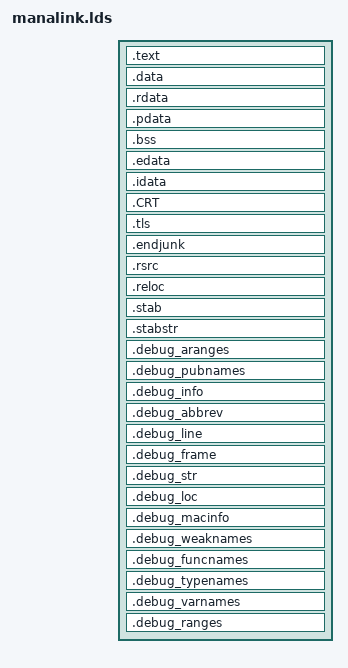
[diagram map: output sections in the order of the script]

/* Global variables */
/*old _cards_ptr = 0x55d0e0;*/
_ability_tooltip_names_exe = 0x738260;
_active_cards_count = 0x4EF520;
_affected_card = 0x7A398C;
_affected_card_controller = 0x738C84;
_ai_defensive_modifier = 0x78fba4;
_ai_modifier = 0x7A31A8;
_ante = 0x738C88;
_ante_cards = 0x505728;
_artifact_count = 0x4ef1d4;
_attacking_card = 0x739198;
_attacking_card_controller = 0x7a3498;
_basiclandtypes_controlled = 0x4ef460;
_cancel = 0x4EF194;	/* == _spell_fizzled */
_cant_be_responded_to = 0x628b34;
_cards_data = 0x7E7010;
_card_on_stack = 0x739190;
_card_on_stack_controller = 0x739194;
_cards_drawn_this_turn = 0x4ef1f4;
_cards_ptr = 0x73bb00;
_cards_txt = 0x73bae4;
_charge_mana_addr_of_pre_mana_pool = 0x4d9434;
_charge_mana_addr_of_x_value = 0x4d9438;
_charge_mana_addr_of_pay_mana_xbugrw = 0x4d943c;
_charge_mana_addr_of_max_x_value = 0x4d9440;
_coin_flip = 0x470690;
_colors_of_lands_in_play = 0x60a568;
_creature_count = 0x4ef1cc;
_current_phase = 0x4EF184;
_current_turn = 0x628670;
_damage_card = 0x7904f8;
_debug_mode = 0x628530;
_Deck = 0x7a588c;
_deck_ptr = 0x4d7030;
_displayed_x_value = 0x60A438;
_enchantment_count = 0x4ef1dc;
_event_flags = 0x4ef188;
_event_result = 0x6205B4;
_forbid_attack = 0x6205b0;
_game_number = 0x739A18;
_game_type = 0x73bad4;
_gauntlet_round = 0x78FA6C;
_graveyard_ptr_mutable = 0x4D7018;
_hand_count = 0x4EF1C4;
_hunting_subtypes = 0x7906B7;
_initial_library = 0x56595c;
_land_can_be_played = 0x4ef190;
_lands_played = 0x4EF1FC;
_ldoubleclicked = 0x60a440;
_life = 0x4EF528;
_life_gained = 0x73b6ac;
_landsofcolor_controlled = 0x4ef4a0;
_mana_doesnt_drain_from_pool = 0x4ef200;
_max_x_value = 0x4ef198;
_must_attack = 0x4EF170;
_needed_mana_colors = 0x7a2b68;
_number_of_attackers_declared = 0x4ef20e;
_opponent_name = 0x628b70;
_opponent_skill = 0x60A430;
_option_PhaseStoppers = 0x62c374;
_player_bits = 0x4ef1a4;
_pumpable_power = 0x628C80;
_pumpable_toughness = 0x628C88;
_player_counters = 0x4EF530;
_raw_card_instances = 0x4ef540;
_raw_displayed_card_instances = 0x543c10;
_raw_mana_available = 0x4ef3c0;
_raw_mana_available_hex = 0x4EF21C;
_reason_for_trigger_controller = 0x737E1C;
_rfg_ptr = 0x4d7024;
_spell_fizzled = 0x4EF194;	/* == _cancel */
_start_usertime_of_current_thread_in_ms = 0x56bf64;
_suppress_draw = 0x786DC8;
_tapped_for_mana_color = 0x7904bc;
_text_lines = 0x715CAC;
_timestamp_card = 0x5076f0;
_timestamp_player = 0x507ec0;
_total_power_of_creatures_by_color = 0x739d60;
_total_toughness_of_creatures_by_color = 0x73a230;
_trigger_cause = 0x739A20;
_trigger_cause_controller = 0x62C17C;
_trigger_condition = 0x7A2D78;
_turn_count = 0x78F260;
_types_of_cards_in_graveyard = 0x4ef174;
_types_of_cards_on_bf = 0x4ef17c;
_x_value = 0x4EF1A0;
/*_u55F028 = 0x55F028;*/	/* now at 7c7000 */
_time_walk_flag = 0x4EF18C;
_types_that_dont_untap = 0x78FBA0;
_mana_paid = 0x55CED0;
_mana_pool = 0x4EF4E0;
_available_slots = 0x7375ac;
/*For older versions _card_coded = 0x4EB7F8*/
_card_coded = 0x75C000;
_creatures_dead_this_turn = 0x4EF1F8;
_activation_card = 0x785F90;
_ai_is_speculating = 0x728574;
_stack_cards = 0x5096B0;
_stack_damage_targets = 0x5097b0;
_stack_data = 0x509630;
_stack_phase = 0x715700;
_stack_size = 0x5057A8;
_dword_4EF1B8 = 0x4EF1B8;
_strs_words_to_hack = 0x620d9c;
_strs_words_hacked = 0x787b08;
_num_words_to_hack = 0x738c80;
_strs_words_to_sleight = 0x618d4c;
_strs_words_sleighted = 0x72917c;
_num_words_to_sleight = 0x620d58;

_iid_draw_a_card = 0x735ed4;

_LEGACY_EFFECT_ALADDIN = 0x73bad8;
_LEGACY_EFFECT_ASTERISK = 0x7a3728;
_LEGACY_EFFECT_CHANNEL = 0x7281b8;
_LEGACY_EFFECT_PUMP = 0x790584;
_LEGACY_EFFECT_GENERIC = 0x737e58;
_LEGACY_EFFECT_ITH = 0x62c18c;
_LEGACY_EFFECT_ASWAN = 0x78FA68;
_LEGACY_EFFECT_DISINTEGRATE = 0x7371F8;
_LEGACY_EFFECT_SORCERESS_QUEEN = 0x73b578;
_LEGACY_EFFECT_STONING = 0x7366d4;
_LEGACY_EFFECT_TIME_WALK = 0x737E58;
/*_LEGACY_EFFECT_SIRENS_CALL = 0x620480;*/

/* this is the constant for the rukh egg legacy, that we have changed the code for. */
_LEGACY_EFFECT_CUSTOM = 0x735ed0;
/* And this was Nafs Asp's. */
_LEGACY_EFFECT_ACTIVATED = 0x7286F4;

_pay_mana_xbugrwaU =	0x4EF400;
_PAY_MANA_COLORLESS =	0x4EF400;
_PAY_MANA_BLACK =	0x4EF404;
_PAY_MANA_BLUE =	0x4EF408;
_PAY_MANA_GREEN =	0x4EF40C;
_PAY_MANA_RED =		0x4EF410;
_PAY_MANA_WHITE =	0x4EF414;
_PAY_MANA_ARTIFACT =	0x4EF418;

_MANA_COLORLESS =	0x55CF10;
_MANA_BLACK =		0x55CF11;
_MANA_BLUE =		0x55CF12;
_MANA_GREEN =		0x55CF13;
_MANA_RED =		0x55CF14;
_MANA_WHITE =		0x55CF15;
_MANA_ARTIFACT =	0x55CF16;
_MANA_UNKNOWN =		0x55CF17;

_COST_COLORLESS =	0x55CF18;
_COST_BLACK =		0x55CF19;
_COST_BLUE =		0x55CF1A;
_COST_GREEN =		0x55CF1B;
_COST_RED =		0x55CF1C;
_COST_WHITE =		0x55CF1D;


/* Functions in the exe */
_add_card_to_hand_exe = 0x479620;
_add_one_mana_any_color = 0x4E8224;
_another_copy_attached = 0x4baeb0;
_aura_ability = 0x4bbf30;
_aura_pump = 0x4bc1e0;
_real_bounce_permanent = 0x4A65F0;
_cannot_block_exe = 0x0040B5E0;
_check_hand_for_type = 0x4E77DD;
_check_mana_multi = 0x402BE0;
_choose_a_card = 0x4a9750;
_choose_a_color_exe = 0x4721c0;
_choose_a_number = 0x472120;
_cop2 = 0x4bdc80;
_count_mana = 0x472400;
_damage_creature_or_player = 0x4C8B90;
_damage_player = 0x4A68A0;
/*_deathtouch = 0x4CA9E0;*/
_declare_mana_available = 0x49d430;
_declare_mana_available_hex = 0x49D240;
_discard_exe = 0x433540;
_discard_card_exe = 0x4337a0;
_dispatch_event = 0x4359b0;
_do_action_with_type_in_hand = 0x4E78CA;
_do_dialog = 0x471EB0;
_draw_cards_exe = 0x41C190;
_end_the_game = 0x46A220;
_fear_exe = 0x40B540;
_real_gain_life = 0x4596B0;
_get_random_creature_type = 0x401ca0;
_get_usertime_of_current_thread_in_ms = 0x472c90;
_has_mana = 0x49D510;
_is_tapped = 0x4E81FE;
_islandhome = 0x4C8D30;
_load_text = 0x401F2C;
_obliterate_top_card_of_stack = 0x436930;
_mana_producer_fixed = 0x47B6C0;
_not_dying = 0x471d30;
_pay_mana_maximally_satisfied = 0x42f130;
_produce_mana = 0x49D490;
_pro_black = 0x4CA440;
_real_lose_the_game = 0x4791F0;
_real_put_on_top_of_deck = 0x410FB0;
_raw_put_iid_on_top_of_deck = 0x479d80;
_rearrange_top_3 = 0x4E7483;
_redraw_libraries = 0x468750;
_regenerate = 0x4C5890;
_regenerate_green = 0x4C5AC0;
_regenerate_target_exe = 0x4c59c0;
_remove_card_from_deck = 0x479d10;
_should_ai_play = 0x4377b0;
_show_deck_exe = 0x479360;
_singleplayer_mode = 0x4e95a8;
_strs_hunting_subtypenames = 0x79066c;
_target_player = 0x4E7E26;
_try_to_pay_for_mana_by_autotapping = 0x42f4a0;
_type_tutor =0x4E585D;
_urzatron_parts = 0x459630;
_asp = 0x4c4520;
_trace_mode = 0x790640;
_unknown62BCEC = 0x62BCEC;
_zombie_regen = 0x4C7E30;
_put_card_on_stack = 0x4338F0;
_put_card_on_stack2 = 0x433850;
_internal_rand = 0x44E050;
_oubliette_effect = 0x4597F0;
_create_a_card_type = 0x4A6500;
_save_or_load_data = 0x49f500;
_dword_60A4B0 = 0x60A4B0;
_TENTATIVE_wait_for_network_result = 0x4A70C0;
_TENTATIVE_send_network_result = 0x4A6BC0;
_dblword_628C10 = 0x628C10;
_byte_628C0C = 0x628C0C;

/*_fopen = 0x4D5EE2;*/
/*_fprintf = 0x4D5F72;*/
/*_fclose = 0x4D5F5A;*/
/*_fwrite = 0x4D5EB8;*/
/*_fscanf = 0x4D5ECA;*/
/*_atoi = 0x4D5F42;*/
/*_strcmp = 0x4D5E88;*/
/*_memcmp = 0x4D5EAC;*/
/*_memcpy = 0x4D5280;*/
/*_memset = 0x4D5FBA;*/
/*_sprintf = 0x4D5E94;*/

_u4585f0 = 0x4585f0;
_u4b6860 = 0x4b6860;
_byte_786DD4 = 0x786DD4;
_dispatch_trigger_twice_once_with_each_player_as_reason = 0x4371A0;
_str_Draw_a_card = 0x7377dc;
_put_card_in_graveyard = 0x477EC0;
_call_sub_437E20_unless_ai_is_speculating = 0x471D60;

/* Cards in the exe */
_card_braingeyser_exe = 0x0041BB00;
_card_glorious_anthem = 0x403CD0;
_card_lich_exe = 0x00432300;
_card_magical_hack_exe = 0x4A45B0;
_card_manta_riders = 0x4D9790;
_card_master_decoy = 0x40E510;
_card_shock = 0x4134B0;
_card_sleight_of_mind_exe = 0x4A49F0;
_card_volcanic_hammer = 0x4A3F20;
_card_zombie_master_exe = 0x004E203F;
_card_fireball_exe = 0x40A980;
_card_disintegrate_exe = 0x41E850;
_card_spell_blast_exe = 0x40A740;
_card_power_sink_exe = 0x4A5150;
_card_detonate_exe = 0x41CEC0;
_card_whimsy_exe = 0x473F50;
_card_word_of_binding_exe = 0x41D150;
_card_winter_blast_exe = 0x4117C0;
_card_alabaster_potion_exe = 0x4A5730;
_card_farmstead_exe = 0x4314A0;
_card_ancestral_recall_exe = 0x4A2C50;
_card_swords_to_plowshares_exe =0x4A3750;
_card_guardian_angel_exe = 0x00474D90;
_card_river_boa = 0x0040D650;
_card_ghazban_ogre = 0x00452D40;
_card_relic_bind = 0x004B7310;
_card_assembly_worker_exe = 0x47AE00;

/*
_card_aladdin_exe = 0x450F90;
_card_animate_artifact_exe = 0x4B5ED0;
_card_aven_fisher_exe = 0x404BE0;
_card_aven_flock_exe = 0x4032F0;
_card_ball_lightning_exe = 0x4CA0F0;
_card_boomerang_exe = 0x42C6D0;
_card_coercion_exe = 0x405980;
_card_consecrate_land_exe = 0x4305E0;
_card_control_magic_exe = 0x4B64C0;
_card_counterspell_exe = 0x4A4FE0;
_card_crusade_exe = 0x4B8E60;
_card_drudge_skeletons_exe = 0x0042B170;
_card_evil_presence_exe = 0x4B8110;
_card_firebreathing_exe = 0x4BA0F0;
_card_hurr_jackal_exe = 0x4CB0F0;
_card_last_gasp_exe = 0x4DEB8F;
_card_lightning_blast_exe = 0x0040DFF0;
_card_lightning_bolt_exe = 0x4A3F20;
_card_lim_duls_high_guard_exe = 0x00405100;
_card_living_lands_exe = 0x4B4A80;
_card_memory_lapse_exe = 0x4DEF65;
_card_orcish_oriflamme_exe = 0x004B8DD0;
_card_pit_scorpion_exe = 0x4C4390;
_card_prodigal_sorcerer_exe = 0x004C8800;
_card_pyroclasm_exe = 0x411280;
_card_remove_soul_exe = 0x0042CEF0;
_card_ring_of_maruf_exe = 0x44FE80;
_card_rod_of_ruin_exe = 0x425F70;
_card_samite_healer_exe = 0x4C79F0;
_card_shivan_dragon_exe = 0x004C4C10;
_card_sylvan_scrying_exe = 0x4E5AD8;
_card_regeneration_exe = 0x4BD5E0;
_card_tawnoss_weaponry_exe = 0x422950;
_card_unsummon_exe = 0x4A41C0;
_card_warriors_honor_exe = 0x004DAB90;
_card_wrath_of_god_exe = 0x0041E480;
_card_sengir_vampire_exe = 0x004C94F0;
_card_daring_apprentice_exe = 0x00408330;
_card_xenic_poltergeist_exe = 0x004C3F60;
_card_nekrataal_exe = 0x00410020;
_card_eladamris_call_exe = 0x004E5B3A;
_card_icy_manipulator_exe = 0x0044EE60;
_card_mogg_fanatic_exe = 0x004DD154;
_card_rabid_wombat_exe = 0x0042AAE0;
_card_strip_mine_exe = 0x0047A2C0;
_card_confiscate_exe = 0x00405930;
_card_spellbook_exe = 0x00413960;
_card_flash_counter_exe = 0x409970;
_card_steal_artifact_exe = 0x4B6510;
_card_winter_orb_exe = 0x426090;
_card_balance_exe = 0x41B800;
_card_kormus_bell_exe = 0x4B48C0;
_card_monstrous_growth_exe = 0x40FBC0;
_card_shatter_exe = 0x4A2E60;
*/

/* Targeting system. Avoid using these outside targets.c */
_target_controller = 0x4D7000;
_target_card = 0x4D7004;
_cards_at_7c7000 = 0x7c7000;
_sub_4378E0 = 0x4378E0;
_set_centerwindow_txt = 0x4386F0;
_sub_45CEC0 = 0x45CEC0;
_sub_45CF00 = 0x45CF00;
_sub_47E980 = 0x47E980;
_sub_47EF10 = 0x47EF10;
_sub_47EF50 = 0x47EF50;
_sub_498F20 = 0x498F20;
_sub_499050 = 0x499050;

/* default linker script */
OUTPUT_FORMAT(pei-i386)
SECTIONS
{
  /* Make the virtual address and file offset synced if the alignment is
     lower than the target page size. */
  . = SIZEOF_HEADERS;
  . = ALIGN(__section_alignment__);
  .text  __image_base__ + ( __section_alignment__ < 0x1000 ? . : __section_alignment__ ) :
  {
    *(.init)
    ManalinkEh.ao(.text)
    *(.text)
    *(SORT(.text$*))
    *(.glue_7t)
    *(.glue_7)
     ___CTOR_LIST__ = .; __CTOR_LIST__ = . ;
            LONG (-1);*(.ctors); *(.ctor); *(SORT(.ctors.*));  LONG (0);
     ___DTOR_LIST__ = .; __DTOR_LIST__ = . ;
            LONG (-1); *(.dtors); *(.dtor); *(SORT(.dtors.*));  LONG (0);
     *(.fini)
    /* ??? Why is .gcc_exc here?  */
     *(.gcc_exc)
    PROVIDE (etext = .);
     *(.gcc_except_table)
  }
  /* The Cygwin32 library uses a section to avoid copying certain data
     on fork.  This used to be named ".data".  The linker used
     to include this between __data_start__ and __data_end__, but that
     breaks building the cygwin32 dll.  Instead, we name the section
     ".data_cygwin_nocopy" and explictly include it after __data_end__. */
  .data BLOCK(__section_alignment__) :
  {
    __data_start__ = . ;
    *(.data)
    *(.data2)
    *(SORT(.data$*))
    *(.jcr)
    __data_end__ = . ;
    *(.data_cygwin_nocopy)
  }
  .rdata BLOCK(__section_alignment__) :
  {
    *(.rdata)
             *(SORT(.rdata$*))
     *(.eh_frame)
    ___RUNTIME_PSEUDO_RELOC_LIST__ = .;
    __RUNTIME_PSEUDO_RELOC_LIST__ = .;
    *(.rdata_runtime_pseudo_reloc)
    ___RUNTIME_PSEUDO_RELOC_LIST_END__ = .;
    __RUNTIME_PSEUDO_RELOC_LIST_END__ = .;
  }
  .pdata BLOCK(__section_alignment__) :
  {
    *(.pdata)
  }
  .bss BLOCK(__section_alignment__) :
  {
    __bss_start__ = . ;
    *(.bss)
    *(COMMON)
    __bss_end__ = . ;
  }
  .edata BLOCK(__section_alignment__) :
  {
    *(.edata)
  }
  /DISCARD/ :
  {
    *(.debug$S)
    *(.debug$T)
    *(.debug$F)
    *(.drectve)
  }
  .idata BLOCK(__section_alignment__) :
  {
    /* This cannot currently be handled with grouped sections.
    See pe.em:sort_sections.  */
    SORT(*)(.idata$2)
    SORT(*)(.idata$3)
    /* These zeroes mark the end of the import list.  */
    LONG (0); LONG (0); LONG (0); LONG (0); LONG (0);
    SORT(*)(.idata$4)
    SORT(*)(.idata$5)
    SORT(*)(.idata$6)
    SORT(*)(.idata$7)
  }
  .CRT BLOCK(__section_alignment__) :
  {
    ___crt_xc_start__ = . ;
    *(SORT(.CRT$XC*))  /* C initialization */
    ___crt_xc_end__ = . ;
    ___crt_xi_start__ = . ;
    *(SORT(.CRT$XI*))  /* C++ initialization */
    ___crt_xi_end__ = . ;
    ___crt_xl_start__ = . ;
    *(SORT(.CRT$XL*))  /* TLS callbacks */
    /* ___crt_xl_end__ is defined in the TLS Directory support code */
    ___crt_xp_start__ = . ;
    *(SORT(.CRT$XP*))  /* Pre-termination */
    ___crt_xp_end__ = . ;
    ___crt_xt_start__ = . ;
    *(SORT(.CRT$XT*))  /* Termination */
    ___crt_xt_end__ = . ;
  }
  .tls BLOCK(__section_alignment__) :
  {
    ___tls_start__ = . ;
    *(.tls)
    *(.tls$)
    *(SORT(.tls$*))
    ___tls_end__ = . ;
  }
  .endjunk BLOCK(__section_alignment__) :
  {
    /* end is deprecated, don't use it */
    PROVIDE (end = .);
    PROVIDE ( _end = .);
     __end__ = .;
  }
  .rsrc BLOCK(__section_alignment__) :
  {
    *(.rsrc)
    *(SORT(.rsrc$*))
  }
  .reloc BLOCK(__section_alignment__) :
  {
    *(.reloc)
  }
  .stab BLOCK(__section_alignment__) (NOLOAD) :
  {
    *(.stab)
  }
  .stabstr BLOCK(__section_alignment__) (NOLOAD) :
  {
    *(.stabstr)
  }
  /* DWARF debug sections.
     Symbols in the DWARF debugging sections are relative to the beginning
     of the section.  Unlike other targets that fake this by putting the
     section VMA at 0, the PE format will not allow it.  */
  /* DWARF 1.1 and DWARF 2.  */
  .debug_aranges BLOCK(__section_alignment__) (NOLOAD) :
  {
    *(.debug_aranges)
  }
  .debug_pubnames BLOCK(__section_alignment__) (NOLOAD) :
  {
    *(.debug_pubnames)
  }
  /* DWARF 2.  */
  .debug_info BLOCK(__section_alignment__) (NOLOAD) :
  {
    *(.debug_info) *(.gnu.linkonce.wi.*)
  }
  .debug_abbrev BLOCK(__section_alignment__) (NOLOAD) :
  {
    *(.debug_abbrev)
  }
  .debug_line BLOCK(__section_alignment__) (NOLOAD) :
  {
    *(.debug_line)
  }
  .debug_frame BLOCK(__section_alignment__) (NOLOAD) :
  {
    *(.debug_frame)
  }
  .debug_str BLOCK(__section_alignment__) (NOLOAD) :
  {
    *(.debug_str)
  }
  .debug_loc BLOCK(__section_alignment__) (NOLOAD) :
  {
    *(.debug_loc)
  }
  .debug_macinfo BLOCK(__section_alignment__) (NOLOAD) :
  {
    *(.debug_macinfo)
  }
  /* SGI/MIPS DWARF 2 extensions.  */
  .debug_weaknames BLOCK(__section_alignment__) (NOLOAD) :
  {
    *(.debug_weaknames)
  }
  .debug_funcnames BLOCK(__section_alignment__) (NOLOAD) :
  {
    *(.debug_funcnames)
  }
  .debug_typenames BLOCK(__section_alignment__) (NOLOAD) :
  {
    *(.debug_typenames)
  }
  .debug_varnames BLOCK(__section_alignment__) (NOLOAD) :
  {
    *(.debug_varnames)
  }
  /* DWARF 3.  */
  .debug_ranges BLOCK(__section_alignment__) (NOLOAD) :
  {
    *(.debug_ranges)
  }
}
